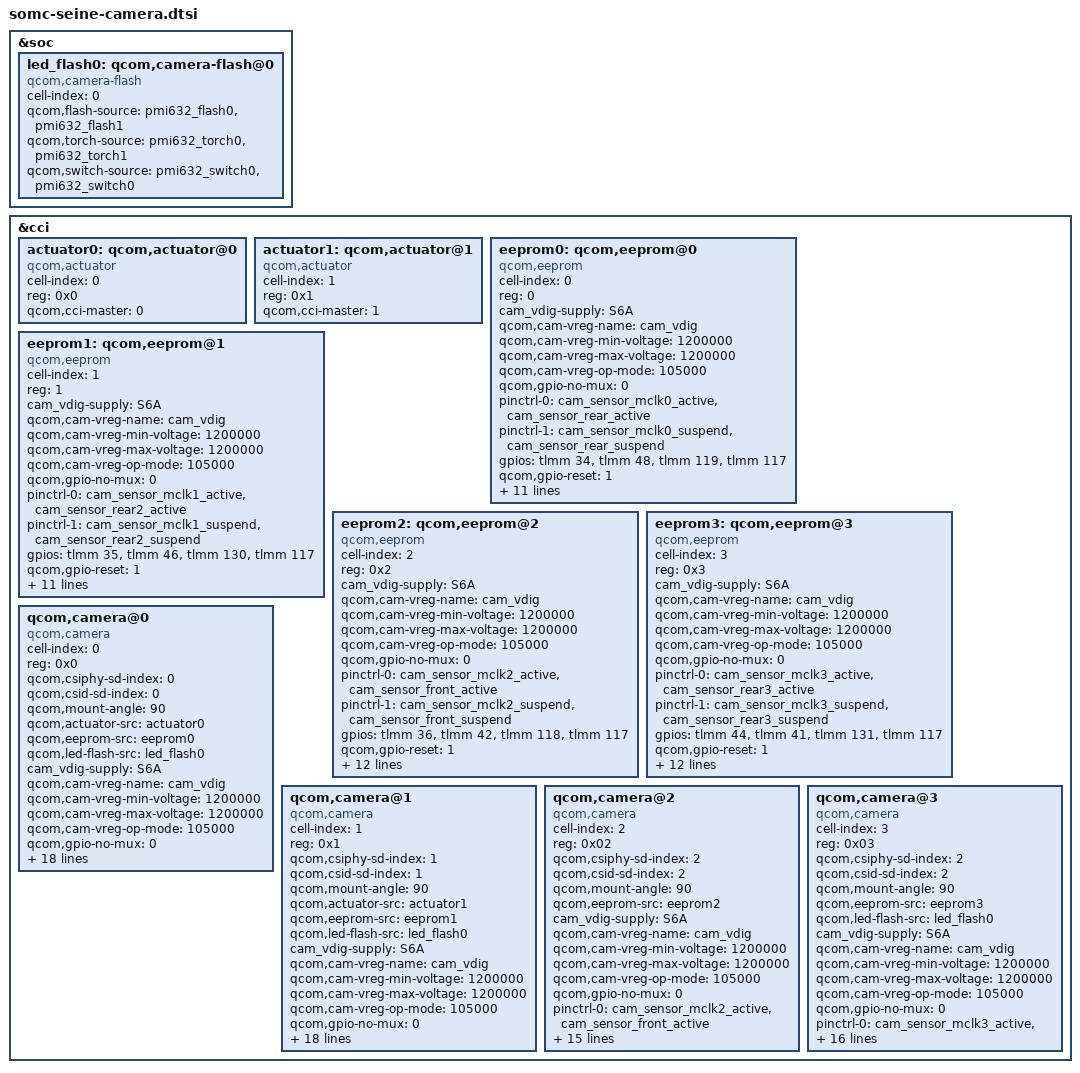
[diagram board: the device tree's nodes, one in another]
// SPDX-License-Identifier: GPL-2.0-only
/*
 * Copyright (c) 2019, The Linux Foundation. All rights reserved.
 */

&soc {
	led_flash0: qcom,camera-flash@0 {
		cell-index = <0>;
		compatible = "qcom,camera-flash";
		qcom,flash-source = <&pmi632_flash0 &pmi632_flash1>;
		qcom,torch-source = <&pmi632_torch0 &pmi632_torch1>;
		qcom,switch-source = <&pmi632_switch0 &pmi632_switch0>;
		status = "ok";
	};
};

&cci {
	#address-cells = <1>;
	#size-cells = <0>;

	actuator0: qcom,actuator@0 {
		cell-index = <0>;
		reg = <0x0>;
		compatible = "qcom,actuator";
		qcom,cci-master = <0>;
	};

	actuator1: qcom,actuator@1 {
		cell-index = <1>;
		reg = <0x1>;
		compatible = "qcom,actuator";
		qcom,cci-master = <1>;
	};

	eeprom0: qcom,eeprom@0 {
		cell-index = <0>;
		reg = <0>;
		compatible = "qcom,eeprom";
		cam_vdig-supply = <&S6A>;
		qcom,cam-vreg-name = "cam_vdig";
		qcom,cam-vreg-min-voltage = <1200000>;
		qcom,cam-vreg-max-voltage = <1200000>;
		qcom,cam-vreg-op-mode = <105000>;
		qcom,gpio-no-mux = <0>;
		pinctrl-names = "cam_default", "cam_suspend";
		pinctrl-0 = <&cam_sensor_mclk0_active
				&cam_sensor_rear_active>;
		pinctrl-1 = <&cam_sensor_mclk0_suspend
				&cam_sensor_rear_suspend>;
		gpios = <&tlmm 34 0>,
			<&tlmm 48 0>,
			<&tlmm 119 0>,
			<&tlmm 117 0>;
		qcom,gpio-reset = <1>;
		qcom,gpio-vdig = <2>;
		qcom,gpio-vio = <3>;
		qcom,gpio-req-tbl-num = <0 1 2 3>;
		qcom,gpio-req-tbl-flags = <1 0 0 2>;
		qcom,gpio-req-tbl-label = "CAMIF_MCLK0",
					"CAM_RESET0", "CAM_VDIG0", "CAM_IO";
		qcom,sensor-position = <0>;
		qcom,cci-master = <0>;
		status = "ok";
		clocks = <&clock_gcc GCC_CAMSS_MCLK0_CLK_SRC>,
				<&clock_gcc GCC_CAMSS_MCLK0_CLK>;
		clock-names = "cam_src_clk", "cam_clk";
		qcom,clock-rates = <24000000 0>;
	};

	eeprom1: qcom,eeprom@1 {
		cell-index = <1>;
		reg = <1>;
		compatible = "qcom,eeprom";
		cam_vdig-supply = <&S6A>;
		qcom,cam-vreg-name = "cam_vdig";
		qcom,cam-vreg-min-voltage = <1200000>;
		qcom,cam-vreg-max-voltage = <1200000>;
		qcom,cam-vreg-op-mode = <105000>;
		qcom,gpio-no-mux = <0>;
		pinctrl-names = "cam_default", "cam_suspend";
		pinctrl-0 = <&cam_sensor_mclk1_active
				 &cam_sensor_rear2_active>;
		pinctrl-1 = <&cam_sensor_mclk1_suspend
				 &cam_sensor_rear2_suspend>;
		gpios = <&tlmm 35 0>,
			<&tlmm 46 0>,
			<&tlmm 130 0>,
			<&tlmm 117 0>;
		qcom,gpio-reset = <1>;
		qcom,gpio-vdig = <2>;
		qcom,gpio-vio = <3>;
		qcom,gpio-req-tbl-num = <0 1 2 3>;
		qcom,gpio-req-tbl-flags = <1 0 0 2>;
		qcom,gpio-req-tbl-label = "CAMIF_MCLK1",
					  "CAM_RESET1", "CAM_VDIG1", "CAM_IO1";
		qcom,sensor-position = <0>;
		qcom,cci-master = <1>;
		status = "ok";
		clocks = <&clock_gcc GCC_CAMSS_MCLK1_CLK_SRC>,
			<&clock_gcc GCC_CAMSS_MCLK1_CLK>;
		clock-names = "cam_src_clk", "cam_clk";
		qcom,clock-rates = <24000000 0>;
	};

	eeprom2: qcom,eeprom@2 {
		cell-index = <2>;
		reg = <0x2>;
		compatible = "qcom,eeprom";
		cam_vdig-supply = <&S6A>;
		qcom,cam-vreg-name = "cam_vdig";
		qcom,cam-vreg-min-voltage = <1200000>;
		qcom,cam-vreg-max-voltage = <1200000>;
		qcom,cam-vreg-op-mode = <105000>;
		qcom,gpio-no-mux = <0>;
		pinctrl-names = "cam_default", "cam_suspend";
		pinctrl-0 = <&cam_sensor_mclk2_active
				 &cam_sensor_front_active>;
		pinctrl-1 = <&cam_sensor_mclk2_suspend
				 &cam_sensor_front_suspend>;
		gpios = <&tlmm 36 0>,
			<&tlmm 42 0>,
			<&tlmm 118 0>,
			<&tlmm 117 0>;
		qcom,gpio-reset = <1>;
		qcom,gpio-vdig = <2>;
		qcom,gpio-vio = <3>;
		qcom,gpio-req-tbl-num = <0 1 2 3>;
		qcom,gpio-req-tbl-flags = <1 0 0 2>;
		qcom,gpio-req-tbl-label = "CAMIF_MCLK0",
					"CAM_RESET2", "CAM_VDIG2", "CAM_IO";
		qcom,sensor-position = <0>;
		qcom,sensor-mode = <0>;
		qcom,cci-master = <0>;
		status = "ok";
		clocks = <&clock_gcc GCC_CAMSS_MCLK2_CLK_SRC>,
		    <&clock_gcc GCC_CAMSS_MCLK2_CLK>;
		clock-names = "cam_src_clk", "cam_clk";
		qcom,clock-rates = <24000000 0>;
	};

	eeprom3: qcom,eeprom@3 {
		cell-index = <3>;
		reg = <0x3>;
		compatible = "qcom,eeprom";
		cam_vdig-supply = <&S6A>;
		qcom,cam-vreg-name = "cam_vdig";
		qcom,cam-vreg-min-voltage = <1200000>;
		qcom,cam-vreg-max-voltage = <1200000>;
		qcom,cam-vreg-op-mode = <105000>;
		qcom,gpio-no-mux = <0>;
		pinctrl-names = "cam_default", "cam_suspend";
		pinctrl-0 = <&cam_sensor_mclk3_active
				 &cam_sensor_rear3_active>;
		pinctrl-1 = <&cam_sensor_mclk3_suspend
				 &cam_sensor_rear3_suspend>;
		gpios = <&tlmm 44 0>,
			<&tlmm 41 0>,
			<&tlmm 131 0>,
			<&tlmm 117 0>;
		qcom,gpio-reset = <1>;
		qcom,gpio-vdig = <2>;
		qcom,gpio-vio = <3>;
		qcom,gpio-req-tbl-num = <0 1 2 3>;
		qcom,gpio-req-tbl-flags = <1 0 0 2>;
		qcom,gpio-req-tbl-label = "CAMIF_MCLK3",
					"CAM_RESET3", "CAM_VDIG3", "CAM_IO";
		qcom,sensor-position = <0>;
		qcom,sensor-mode = <0>;
		qcom,cci-master = <1>;
		status = "ok";
		clocks = <&clock_gcc GCC_CAMSS_MCLK3_CLK_SRC>,
		    <&clock_gcc GCC_CAMSS_MCLK3_CLK>;
		clock-names = "cam_src_clk", "cam_clk";
		qcom,clock-rates = <24000000 0>;
	};

	qcom,camera@0 {
		cell-index = <0>;
		compatible = "qcom,camera";
		reg = <0x0>;
		qcom,csiphy-sd-index = <0>;
		qcom,csid-sd-index = <0>;
		qcom,mount-angle = <90>;
		qcom,actuator-src = <&actuator0>;
		qcom,eeprom-src = <&eeprom0>;
		qcom,led-flash-src = <&led_flash0>;
		cam_vdig-supply = <&S6A>;
		qcom,cam-vreg-name = "cam_vdig";
		qcom,cam-vreg-min-voltage = <1200000>;
		qcom,cam-vreg-max-voltage = <1200000>;
		qcom,cam-vreg-op-mode = <105000>;
		qcom,gpio-no-mux = <0>;
		pinctrl-names = "cam_default", "cam_suspend";
		pinctrl-0 = <&cam_sensor_mclk0_active
				&cam_sensor_rear_active>;
		pinctrl-1 = <&cam_sensor_mclk0_suspend
				&cam_sensor_rear_suspend>;
		gpios = <&tlmm 34 0>,
			<&tlmm 48 0>,
			<&tlmm 119 0>,
			<&tlmm 117 0>;
		qcom,gpio-reset = <1>;
		qcom,gpio-vdig = <2>;
		qcom,gpio-vio = <3>;
		qcom,gpio-req-tbl-num = <0 1 2 3>;
		qcom,gpio-req-tbl-flags = <1 0 0 2>;
		qcom,gpio-req-tbl-label = "CAMIF_MCLK0",
					"CAM_RESET0", "CAM_VDIG0", "CAM_IO";
		qcom,sensor-position = <0>;
		qcom,sensor-mode = <0>;
		qcom,cci-master = <0>;
		status = "ok";
		clocks = <&clock_gcc GCC_CAMSS_MCLK0_CLK_SRC>,
				<&clock_gcc GCC_CAMSS_MCLK0_CLK>;
		clock-names = "cam_src_clk", "cam_clk";
		qcom,clock-rates = <24000000 0>;
	};

	qcom,camera@1 {
		cell-index = <1>;
		compatible = "qcom,camera";
		reg = <0x1>;
		qcom,csiphy-sd-index = <1>;
		qcom,csid-sd-index = <1>;
		qcom,mount-angle = <90>;
		qcom,actuator-src = <&actuator1>;
		qcom,eeprom-src = <&eeprom1>;
		qcom,led-flash-src = <&led_flash0>;
		cam_vdig-supply = <&S6A>;
		qcom,cam-vreg-name = "cam_vdig";
		qcom,cam-vreg-min-voltage = <1200000>;
		qcom,cam-vreg-max-voltage = <1200000>;
		qcom,cam-vreg-op-mode = <105000>;
		qcom,gpio-no-mux = <0>;
		pinctrl-names = "cam_default", "cam_suspend";
		pinctrl-0 = <&cam_sensor_mclk1_active
				 &cam_sensor_rear2_active>;
		pinctrl-1 = <&cam_sensor_mclk1_suspend
				 &cam_sensor_rear2_suspend>;
		gpios = <&tlmm 35 0>,
			<&tlmm 46 0>,
			<&tlmm 130 0>,
			<&tlmm 117 0>;
		qcom,gpio-reset = <1>;
		qcom,gpio-vdig = <2>;
		qcom,gpio-vio = <3>;
		qcom,gpio-req-tbl-num = <0 1 2 3>;
		qcom,gpio-req-tbl-flags = <1 0 0 2>;
		qcom,gpio-req-tbl-label = "CAMIF_MCLK1",
					  "CAM_RESET1", "CAM_VDIG1", "CAM_IO1";
		qcom,sensor-position = <0>;
		qcom,sensor-mode = <0>;
		qcom,cci-master = <1>;
		status = "ok";
		clocks = <&clock_gcc GCC_CAMSS_MCLK1_CLK_SRC>,
			<&clock_gcc GCC_CAMSS_MCLK1_CLK>;
		clock-names = "cam_src_clk", "cam_clk";
		qcom,clock-rates = <24000000 0>;
	};

	qcom,camera@2 {
		cell-index = <2>;
		compatible = "qcom,camera";
		reg = <0x02>;
		qcom,csiphy-sd-index = <2>;
		qcom,csid-sd-index = <2>;
		qcom,mount-angle = <90>;
		qcom,eeprom-src = <&eeprom2>;
		cam_vdig-supply = <&S6A>;
		qcom,cam-vreg-name = "cam_vdig";
		qcom,cam-vreg-min-voltage = <1200000>;
		qcom,cam-vreg-max-voltage = <1200000>;
		qcom,cam-vreg-op-mode = <105000>;
		qcom,gpio-no-mux = <0>;
		pinctrl-names = "cam_default", "cam_suspend";
		pinctrl-0 = <&cam_sensor_mclk2_active
				 &cam_sensor_front_active>;
		pinctrl-1 = <&cam_sensor_mclk2_suspend
				 &cam_sensor_front_suspend>;
		gpios = <&tlmm 36 0>,
			<&tlmm 42 0>,
			<&tlmm 118 0>,
			<&tlmm 117 0>;
		qcom,gpio-reset = <1>;
		qcom,gpio-vdig = <2>;
		qcom,gpio-vio = <3>;
		qcom,gpio-req-tbl-num = <0 1 2 3>;
		qcom,gpio-req-tbl-flags = <1 0 0 2>;
		qcom,gpio-req-tbl-label = "CAMIF_MCLK2",
					"CAM_RESET2", "CAM_VDIG2", "CAM_IO2";
		qcom,sensor-mode = <0>;
		qcom,cci-master = <0>;
		status = "ok";
		clocks = <&clock_gcc GCC_CAMSS_MCLK2_CLK_SRC>,
			<&clock_gcc GCC_CAMSS_MCLK2_CLK>;
		clock-names = "cam_src_clk", "cam_clk";
		qcom,clock-rates = <24000000 0>;
	};

	qcom,camera@3 {
		cell-index = <3>;
		compatible = "qcom,camera";
		reg = <0x03>;
		qcom,csiphy-sd-index = <2>;
		qcom,csid-sd-index = <2>;
		qcom,mount-angle = <90>;
		qcom,eeprom-src = <&eeprom3>;
		qcom,led-flash-src = <&led_flash0>;
		cam_vdig-supply = <&S6A>;
		qcom,cam-vreg-name = "cam_vdig";
		qcom,cam-vreg-min-voltage = <1200000>;
		qcom,cam-vreg-max-voltage = <1200000>;
		qcom,cam-vreg-op-mode = <105000>;
		qcom,gpio-no-mux = <0>;
		pinctrl-names = "cam_default", "cam_suspend";
		pinctrl-0 = <&cam_sensor_mclk3_active
				 &cam_sensor_rear3_active>;
		pinctrl-1 = <&cam_sensor_mclk3_suspend
				 &cam_sensor_rear3_suspend>;
		gpios = <&tlmm 44 0>,
			<&tlmm 41 0>,
			<&tlmm 131 0>,
			<&tlmm 117 0>;
		qcom,gpio-reset = <1>;
		qcom,gpio-vdig = <2>;
		qcom,gpio-vio = <3>;
		qcom,gpio-req-tbl-num = <0 1 2 3>;
		qcom,gpio-req-tbl-flags = <1 0 0 2>;
		qcom,gpio-req-tbl-label = "CAMIF_MCLK3",
					"CAM_RESET3", "CAM_VDIG3", "CAM_IO3";
		qcom,sensor-mode = <0>;
		qcom,cci-master = <1>;
		status = "ok";
		clocks = <&clock_gcc GCC_CAMSS_MCLK3_CLK_SRC>,
			<&clock_gcc GCC_CAMSS_MCLK3_CLK>;
		clock-names = "cam_src_clk", "cam_clk";
		qcom,clock-rates = <24000000 0>;
	};
};
